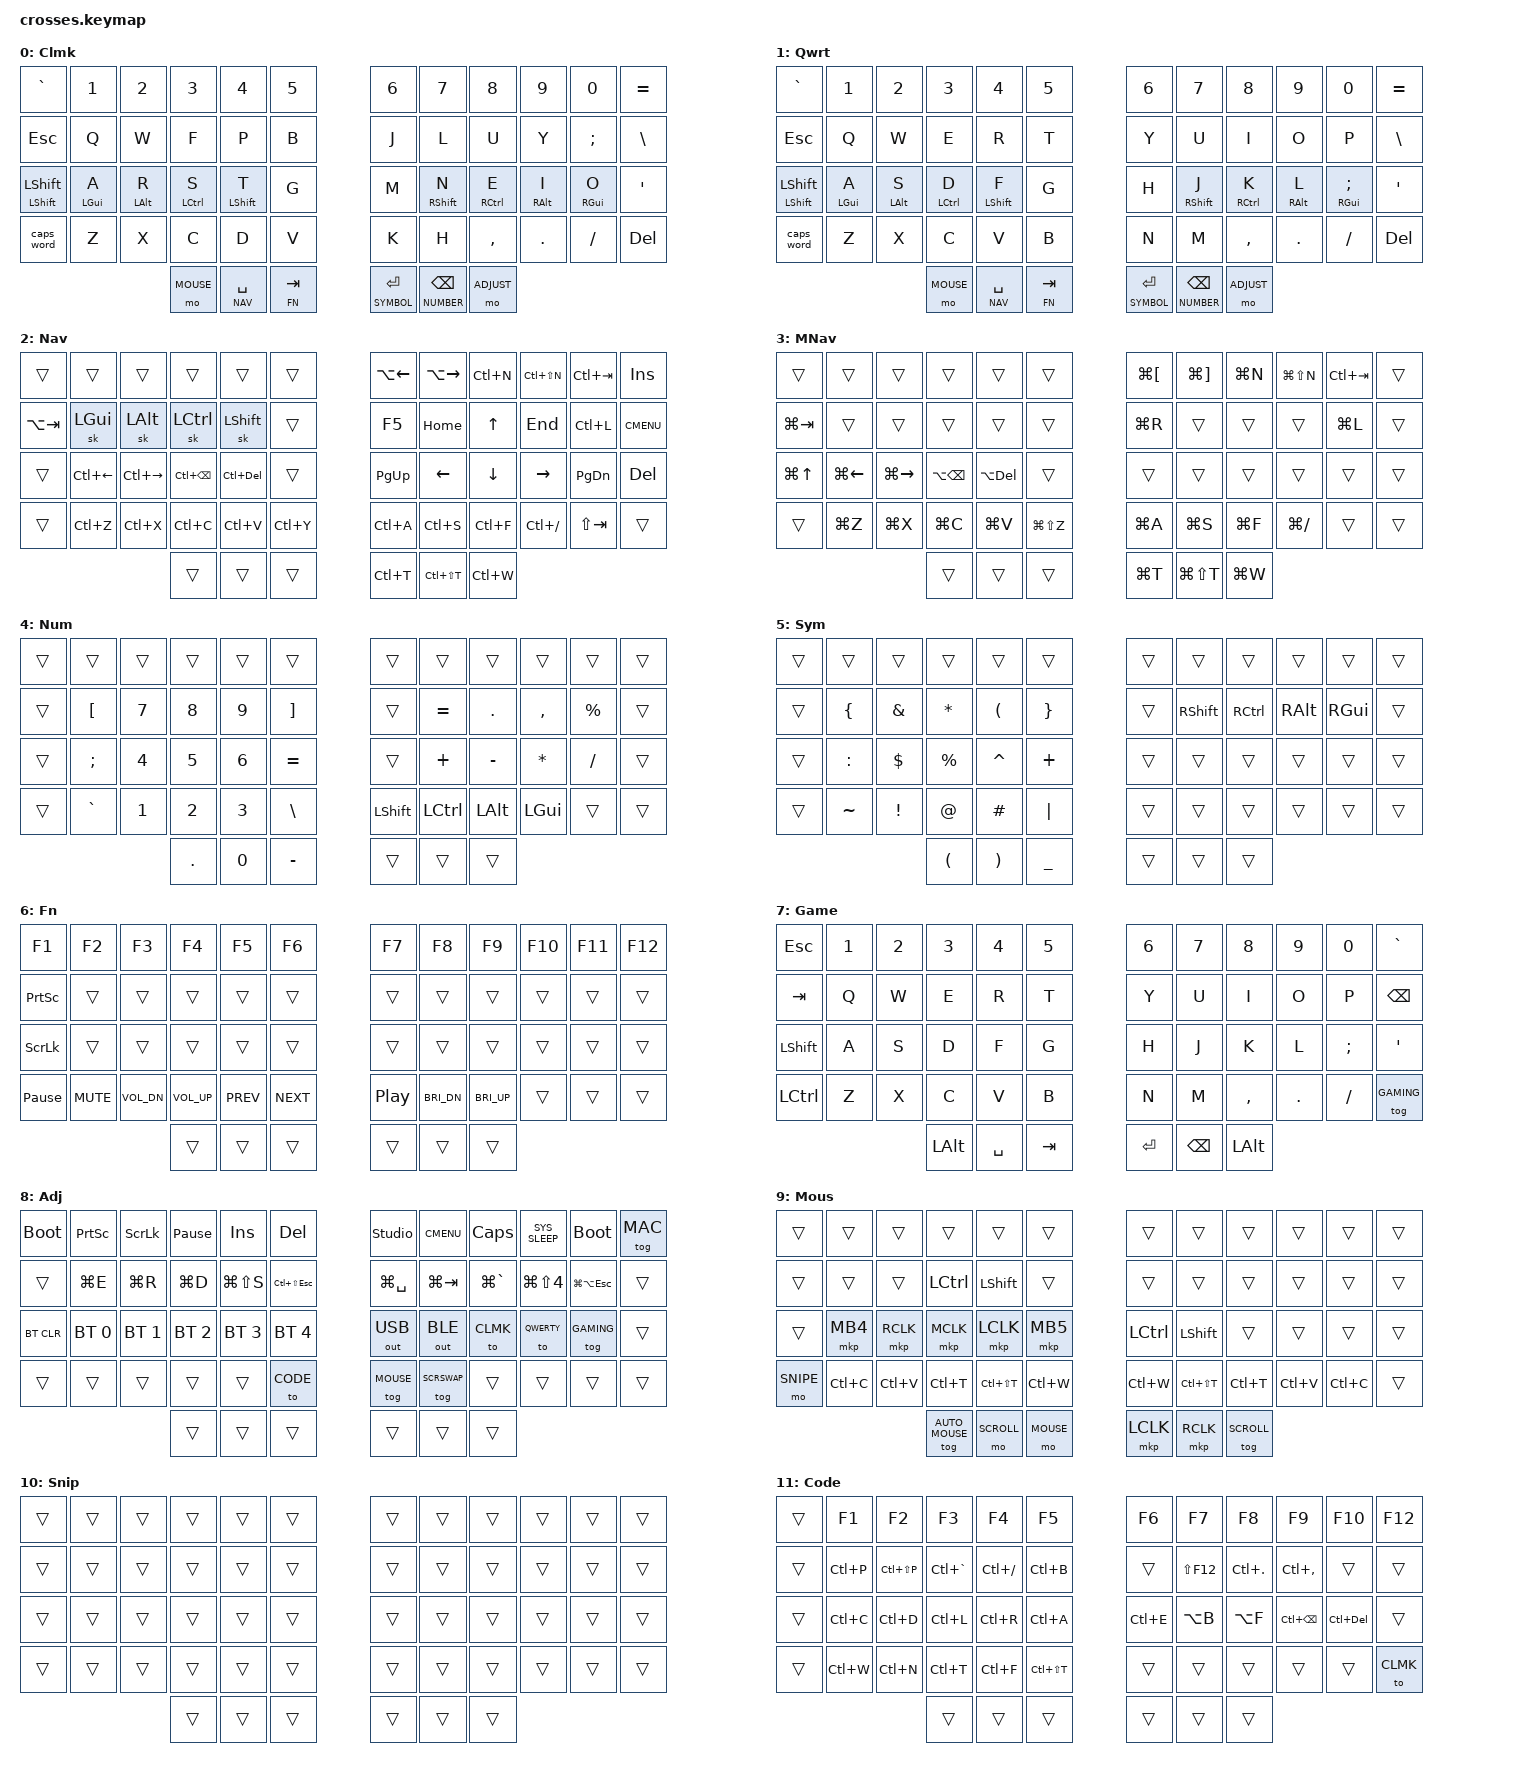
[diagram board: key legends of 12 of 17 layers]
#include <behaviors.dtsi>
#include <dt-bindings/zmk/bt.h>
#include <dt-bindings/zmk/keys.h>
#include <dt-bindings/zmk/outputs.h>
#include <dt-bindings/zmk/pointing.h>

#define CLMK     0
#define QWERTY   1
#define NAV      2
#define MAC_NAV  3
#define NUMBER   4
#define SYMBOL   5
#define FN       6
#define GAMING   7
#define ADJUST   8
#define MOUSE    9
#define SNIPE    10
#define CODE     11
#define MAC      12
#define SCRSWAP    13
#define SCROLL     14
#define AUTO_MOUSE 15
#define MAC_MOUSE  16

#define ___ &trans
#define XXX &none

&caps_word {
    continue-list = <MINUS UNDERSCORE BACKSPACE DELETE N0 N1 N2 N3 N4 N5 N6 N7 N8 N9>;
};

&lt {
    flavor = "balanced";
    tapping-term-ms = <200>;
    // Tap, then re-press within 200ms: the second press is treated as a tap
    // even when held. Lets you hold the BSPC/SPACE thumb to repeat after a
    // first tap, instead of triggering the layer.
    quick-tap-ms = <200>;
};

&mt {
    flavor = "tap-preferred";
    tapping-term-ms = <220>;
    quick-tap-ms = <175>;
};

&sk {
    release-after-ms = <900>;
    quick-release;
};

/ {
    behaviors {
        hml: homerow_mod_left {
            compatible = "zmk,behavior-hold-tap";
            #binding-cells = <2>;
            flavor = "balanced";
            tapping-term-ms = <220>;
            quick-tap-ms = <175>;
            require-prior-idle-ms = <150>;
            hold-trigger-on-release;
            bindings = <&kp>, <&kp>;
            hold-trigger-key-positions = <6 7 8 9 10 11 18 19 20 21 22 23 30 31 32 33 34 35 42 43 44 45 46 47 51 52 53>;
        };

        hmr: homerow_mod_right {
            compatible = "zmk,behavior-hold-tap";
            #binding-cells = <2>;
            flavor = "balanced";
            tapping-term-ms = <220>;
            quick-tap-ms = <175>;
            require-prior-idle-ms = <150>;
            hold-trigger-on-release;
            bindings = <&kp>, <&kp>;
            hold-trigger-key-positions = <0 1 2 3 4 5 12 13 14 15 16 17 24 25 26 27 28 29 36 37 38 39 40 41 48 49 50>;
        };

        magic_shift: magic_shift {
            compatible = "zmk,behavior-hold-tap";
            #binding-cells = <2>;
            flavor = "balanced";
            tapping-term-ms = <200>;
            quick-tap-ms = <175>;
            bindings = <&kp>, <&sk>;
        };
    };

    macros {
        // Modifier-held mouse clicks for the Mouse layer. The macro presses
        // the modifier, taps left click, releases the modifier so OS sees a
        // proper Ctrl-click / Shift-click / Cmd-click event.
        ctrl_click: ctrl_click {
            compatible = "zmk,behavior-macro";
            #binding-cells = <0>;
            bindings
                = <&macro_press &kp LCTRL>
                , <&macro_tap &mkp LCLK>
                , <&macro_release &kp LCTRL>
                ;
        };
        shift_click: shift_click {
            compatible = "zmk,behavior-macro";
            #binding-cells = <0>;
            bindings
                = <&macro_press &kp LSHFT>
                , <&macro_tap &mkp LCLK>
                , <&macro_release &kp LSHFT>
                ;
        };
        cmd_click: cmd_click {
            compatible = "zmk,behavior-macro";
            #binding-cells = <0>;
            bindings
                = <&macro_press &kp LGUI>
                , <&macro_tap &mkp LCLK>
                , <&macro_release &kp LGUI>
                ;
        };
    };

    conditional_layers {
        compatible = "zmk,conditional-layers";
        // While MAC mode is toggled on, holding NAV brings up the Mac-flavored
        // overlay that swaps Ctrl-prefixed clipboard/word ops to Cmd/Opt.
        mac_nav_overlay {
            if-layers = <NAV MAC>;
            then-layer = <MAC_NAV>;
        };
        // While MAC mode is toggled, the Mouse layer's modifier-click macros
        // swap to use Cmd instead of Ctrl.
        mac_mouse_overlay {
            if-layers = <MOUSE MAC>;
            then-layer = <MAC_MOUSE>;
        };
        mac_auto_mouse_overlay {
            if-layers = <AUTO_MOUSE MAC>;
            then-layer = <MAC_MOUSE>;
        };
    };

    combos {
        compatible = "zmk,combos";
        // urob-style: short timeout (~30ms) + require-prior-idle (150ms) so
        // the combo only fires when you've been idle for a moment, not in
        // the middle of a fast roll. Layer-restricted to base alphas.

        // MAC toggle: Z + / (bottom-row diagonal corners). Deliberate.
        combo_mac_toggle {
            timeout-ms = <50>;
            require-prior-idle-ms = <150>;
            key-positions = <37 46>;
            bindings = <&tog MAC>;
            layers = <CLMK QWERTY>;
        };
        // Parens on the right home row: N+E and E+I. Fires Ctrl/Cmd-correct
        // characters via &kp LPAR/RPAR (these are scancodes, not modifier
        // shortcuts, so they work the same on Win and Mac).
        combo_lpar {
            timeout-ms = <30>;
            require-prior-idle-ms = <150>;
            key-positions = <31 32>;
            bindings = <&kp LPAR>;
            layers = <CLMK QWERTY>;
        };
        combo_rpar {
            timeout-ms = <30>;
            require-prior-idle-ms = <150>;
            key-positions = <32 33>;
            bindings = <&kp RPAR>;
            layers = <CLMK QWERTY>;
        };
        // Cut/Copy/Paste on the left bottom row, urob-style. These fire
        // Ctrl-prefixed shortcuts; use Mouse/MacMouse for OS-aware commands.
        combo_copy {
            timeout-ms = <30>;
            require-prior-idle-ms = <150>;
            key-positions = <38 39>;
            bindings = <&kp LC(C)>;
            layers = <CLMK QWERTY>;
        };
        combo_paste {
            timeout-ms = <30>;
            require-prior-idle-ms = <150>;
            key-positions = <39 40>;
            bindings = <&kp LC(V)>;
            layers = <CLMK QWERTY>;
        };
        combo_cut {
            timeout-ms = <30>;
            require-prior-idle-ms = <150>;
            key-positions = <38 40>;
            bindings = <&kp LC(X)>;
            layers = <CLMK QWERTY>;
        };
        combo_square_left {
            timeout-ms = <30>;
            require-prior-idle-ms = <150>;
            key-positions = <43 44>;
            bindings = <&kp LBKT>;
            layers = <CLMK QWERTY>;
        };
        combo_square_right {
            timeout-ms = <30>;
            require-prior-idle-ms = <150>;
            key-positions = <44 45>;
            bindings = <&kp RBKT>;
            layers = <CLMK QWERTY>;
        };
        combo_gaming_toggle {
            timeout-ms = <50>;
            require-prior-idle-ms = <150>;
            key-positions = <38 45>;
            bindings = <&tog GAMING>;
            layers = <CLMK QWERTY>;
        };
    };

    chosen { zmk,physical-layout = &gggw_crosses_54_layout; };

    keymap {
        compatible = "zmk,keymap";

        clmk_layer {
            display-name = "Clmk";
            bindings = <
                &kp GRAVE      &kp N1        &kp N2        &kp N3        &kp N4          &kp N5        &kp N6       &kp N7          &kp N8        &kp N9       &kp N0         &kp EQUAL
                &kp ESC        &kp Q         &kp W         &kp F         &kp P           &kp B         &kp J        &kp L           &kp U         &kp Y        &kp SEMI       &kp BSLH
                &magic_shift LSHFT LSHFT &hml LGUI A &hml LALT R &hml LCTRL S &hml LSHFT T &kp G        &kp M        &hmr RSHFT N    &hmr RCTRL E  &hmr RALT I  &hmr RGUI O    &kp SQT
                &caps_word     &kp Z         &kp X         &kp C         &kp D           &kp V         &kp K        &kp H           &kp COMMA     &kp DOT      &kp FSLH       &kp DEL
                                                            &mo MOUSE                   &lt NAV SPACE &lt FN TAB   &lt SYMBOL RET  &lt NUMBER BSPC &mo ADJUST
            >;
        };

        qwerty_layer {
            display-name = "Qwrt";
            bindings = <
                &kp GRAVE      &kp N1        &kp N2        &kp N3        &kp N4          &kp N5        &kp N6       &kp N7          &kp N8        &kp N9       &kp N0         &kp EQUAL
                &kp ESC        &kp Q         &kp W         &kp E         &kp R           &kp T         &kp Y        &kp U           &kp I         &kp O        &kp P          &kp BSLH
                &magic_shift LSHFT LSHFT &hml LGUI A &hml LALT S &hml LCTRL D &hml LSHFT F &kp G        &kp H        &hmr RSHFT J    &hmr RCTRL K  &hmr RALT L  &hmr RGUI SEMI &kp SQT
                &caps_word     &kp Z         &kp X         &kp C         &kp V           &kp B         &kp N        &kp M           &kp COMMA     &kp DOT      &kp FSLH       &kp DEL
                                                            &mo MOUSE                   &lt NAV SPACE &lt FN TAB   &lt SYMBOL RET  &lt NUMBER BSPC &mo ADJUST
            >;
        };

        nav_layer {
            display-name = "Nav";
            // Row 1 left = clipboard ops with explicit Ctrl modifiers (the
            // K_UNDO/K_CUT system keycodes are inert on Win and Mac).
            // Arrows on row 3 (home row) so they sit under your right hand.
            // Row 2 right is the wider nav cluster (Home/PgDn/PgUp/End).
            bindings = <
                ___            ___           ___           ___           ___             ___           &kp LA(LEFT) &kp LA(RIGHT)   &kp LC(N)     &kp LC(LS(N)) &kp LC(TAB)   &kp INS
                &kp LA(TAB)    &sk LGUI      &sk LALT      &sk LCTRL     &sk LSHFT       ___           &kp F5       &kp HOME        &kp UP        &kp END      &kp LC(L)      &kp K_CMENU
                ___            &kp LC(LEFT)  &kp LC(RIGHT) &kp LC(BSPC)  &kp LC(DEL)     ___           &kp PG_UP    &kp LEFT        &kp DOWN      &kp RIGHT    &kp PG_DN      &kp DEL
                ___            &kp LC(Z)     &kp LC(X)     &kp LC(C)     &kp LC(V)       &kp LC(Y)     &kp LC(A)    &kp LC(S)       &kp LC(F)     &kp LC(FSLH) &kp LS(TAB)    ___
                                                            ___                       ___           ___          &kp LC(T)       &kp LC(LS(T)) &kp LC(W)
            >;
        };

        mac_nav_layer {
            display-name = "MNav";
            // Conditional overlay; only fires when MAC + NAV are both active.
            // Overrides only the keys whose modifier differs on macOS.
            // Cmd+Shift+Z is Mac redo. Word motion uses Opt instead of Ctrl.
            bindings = <
                ___            ___           ___           ___           ___             ___           &kp LG(LBKT) &kp LG(RBKT)    &kp LG(N)     &kp LG(LS(N)) &kp LC(TAB)   ___
                &kp LG(TAB)    ___           ___           ___           ___             ___           &kp LG(R)    ___             ___           ___          &kp LG(L)      ___
                &kp LG(UP)     &kp LG(LEFT)  &kp LG(RIGHT) &kp LA(BSPC)  &kp LA(DEL)     ___           ___          ___             ___           ___          ___            ___
                ___            &kp LG(Z)     &kp LG(X)     &kp LG(C)     &kp LG(V)       &kp LG(LS(Z)) &kp LG(A)    &kp LG(S)       &kp LG(F)     &kp LG(FSLH) ___            ___
                                                            ___                       ___           ___          &kp LG(T)       &kp LG(LS(T)) &kp LG(W)
            >;
        };

        number_layer {
            display-name = "Num";
            bindings = <
                ___            ___           ___           ___           ___             ___           ___          ___            ___          ___         ___            ___
                ___            &kp LBKT      &kp N7        &kp N8        &kp N9          &kp RBKT      ___          &kp EQUAL      &kp DOT      &kp COMMA   &kp PRCNT      ___
                ___            &kp SEMI      &kp N4        &kp N5        &kp N6          &kp EQUAL     ___          &kp PLUS       &kp MINUS    &kp ASTRK   &kp FSLH       ___
                ___            &kp GRAVE     &kp N1        &kp N2        &kp N3          &kp BSLH      &kp LSHFT    &kp LCTRL      &kp LALT     &kp LGUI    ___            ___
                                                            &kp DOT                   &kp N0        &kp MINUS    ___             ___           ___
            >;
        };

        symbol_layer {
            display-name = "Sym";
            bindings = <
                ___            ___           ___           ___           ___             ___           ___          ___            ___          ___         ___            ___
                ___            &kp LBRC      &kp AMPS      &kp ASTRK     &kp LPAR        &kp RBRC      ___          &kp RSHFT      &kp RCTRL    &kp RALT    &kp RGUI       ___
                ___            &kp COLON     &kp DLLR      &kp PRCNT     &kp CARET       &kp PLUS      ___          ___            ___          ___         ___            ___
                ___            &kp TILDE     &kp EXCL      &kp AT        &kp HASH        &kp PIPE      ___          ___            ___          ___         ___            ___
                                                            &kp LPAR                  &kp RPAR      &kp UNDER    ___             ___           ___
            >;
        };

        fn_layer {
            display-name = "Fn";
            // Cleaned out: just F-keys, system, and media. IDE and terminal
            // shortcuts moved to the Code layer.
            bindings = <
                &kp F1         &kp F2        &kp F3        &kp F4        &kp F5          &kp F6        &kp F7       &kp F8         &kp F9       &kp F10     &kp F11        &kp F12
                &kp PSCRN      ___           ___           ___           ___             ___           ___          ___            ___          ___         ___            ___
                &kp SLCK       ___           ___           ___           ___             ___           ___          ___            ___          ___         ___            ___
                &kp PAUSE_BREAK &kp C_MUTE   &kp C_VOL_DN  &kp C_VOL_UP  &kp C_PREV      &kp C_NEXT    &kp C_PLAY_PAUSE &kp C_BRI_DN &kp C_BRI_UP ___        ___            ___
                                                            ___                       ___           ___          ___             ___           ___
            >;
        };

        gaming_layer {
            display-name = "Game";
            bindings = <
                &kp ESC        &kp N1        &kp N2        &kp N3        &kp N4          &kp N5        &kp N6       &kp N7         &kp N8       &kp N9      &kp N0         &kp GRAVE
                &kp TAB        &kp Q         &kp W         &kp E         &kp R           &kp T         &kp Y        &kp U          &kp I        &kp O       &kp P          &kp BSPC
                &kp LSHFT      &kp A         &kp S         &kp D         &kp F           &kp G         &kp H        &kp J          &kp K        &kp L       &kp SEMI       &kp SQT
                &kp LCTRL      &kp Z         &kp X         &kp C         &kp V           &kp B         &kp N        &kp M          &kp COMMA    &kp DOT     &kp FSLH       &tog GAMING
                                                            &kp LALT                 &kp SPACE     &kp TAB      &kp RET        &kp BSPC      &kp LALT
            >;
        };

        adjust_layer {
            display-name = "Adj";
            // Reached by chording NAV (left thumb) + SYMBOL (right thumb).
            // Row 2 OS shortcuts are Windows-flavored; swap MAC on (row 1
            // col 11) for the Mac overlay (currently only adjusts Nav).
            bindings = <
                &bootloader    &kp PSCRN     &kp SLCK      &kp PAUSE_BREAK &kp INS       &kp DEL       &studio_unlock &kp K_CMENU   &kp CAPSLOCK &kp SYS_SLEEP &bootloader   &tog MAC
                ___            &kp LG(E)     &kp LG(R)     &kp LG(D)       &kp LG(LS(S)) &kp LC(LS(ESC)) &kp LG(SPACE) &kp LG(TAB)   &kp LG(GRAVE) &kp LG(LS(N4)) &kp LG(LA(ESC)) ___
                &bt BT_CLR     &bt BT_SEL 0  &bt BT_SEL 1  &bt BT_SEL 2    &bt BT_SEL 3  &bt BT_SEL 4  &out OUT_USB  &out OUT_BLE  &to CLMK      &to QWERTY    &tog GAMING   ___
                ___            ___           ___           ___             ___           &to CODE      &tog MOUSE    &tog SCRSWAP  ___           ___          ___           ___
                                                            ___                       ___           ___          ___             ___           ___
            >;
        };

        mouse_layer {
            display-name = "Mous";
            // Held momentarily via &mo MOUSE on the left outer thumb, or
            // toggled from Adjust. Click cluster on the left half.
            // Ctrl/Shift are available above MCLK/LCLK and on the left edge
            // of the right click row for one-handed modified clicks.
            // Hold &mo SNIPE (left bottom) for precision. Bottom row has
            // mirrored browser/edit shortcuts; hold &mo SCROLL (left middle
            // thumb) to turn the central ball into a scroll wheel.
            bindings = <
                ___            ___           ___           ___           ___            ___           ___          ___            ___          ___         ___            ___
                ___            ___           ___           &kp LCTRL     &kp LSHFT      ___           ___          ___            ___          ___         ___            ___
                ___            &mkp MB4      &mkp RCLK     &mkp MCLK     &mkp LCLK      &mkp MB5      &kp LCTRL    &kp LSHFT      ___          ___         ___            ___
                &mo SNIPE      &kp LC(C)     &kp LC(V)     &kp LC(T)     &kp LC(LS(T))  &kp LC(W)     &kp LC(W)    &kp LC(LS(T))  &kp LC(T)    &kp LC(V)   &kp LC(C)     ___
                                                            &tog AUTO_MOUSE           &mo SCROLL    &mo MOUSE    &mkp LCLK       &mkp RCLK     &tog SCROLL
            >;
        };

        snipe_layer {
            display-name = "Snip";
            // Activates the snipe override in the right overlay, halving the
            // central trackball to 200 cpi. Clicks fall through.
            bindings = <
                ___            ___           ___           ___           ___            ___           ___          ___            ___          ___         ___            ___
                ___            ___           ___           ___           ___            ___           ___          ___            ___          ___         ___            ___
                ___            ___           ___           ___           ___            ___           ___          ___            ___          ___         ___            ___
                ___            ___           ___           ___           ___            ___           ___          ___            ___          ___         ___            ___
                                                            ___                       ___           ___          ___             ___           ___
            >;
        };

        code_layer {
            display-name = "Code";
            // Reached via &to CODE on the Adjust layer. Right outer thumb
            // exits back to Clmk. IDE shortcuts on row 2; terminal shortcuts
            // on row 3.
            bindings = <
                ___            &kp F1        &kp F2        &kp F3        &kp F4          &kp F5        &kp F6       &kp F7         &kp F8       &kp F9      &kp F10        &kp F12
                ___            &kp LC(P)     &kp LC(LS(P)) &kp LC(GRAVE) &kp LC(FSLH)    &kp LC(B)     ___          &kp LS(F12)    &kp LC(DOT)  &kp LC(COMMA) ___          ___
                ___            &kp LC(C)     &kp LC(D)     &kp LC(L)     &kp LC(R)       &kp LC(A)     &kp LC(E)    &kp LA(B)      &kp LA(F)    &kp LC(BSPC) &kp LC(DEL)   ___
                ___            &kp LC(W)     &kp LC(N)     &kp LC(T)     &kp LC(F)       &kp LC(LS(T)) ___          ___            ___          ___          ___           &to CLMK
                                                            ___                       ___           ___          ___             ___           ___
            >;
        };

        mac_layer {
            display-name = "Mac";
            // Toggle flag layer. Mostly transparent; presence triggers the
            // MAC_NAV conditional overlay. Add per-position Mac overrides
            // here later if needed (Adjust OS shortcuts, etc.).
            bindings = <
                ___            ___           ___           ___           ___            ___           ___          ___            ___          ___         ___            ___
                ___            ___           ___           ___           ___            ___           ___          ___            ___          ___         ___            ___
                ___            ___           ___           ___           ___            ___           ___          ___            ___          ___         ___            ___
                ___            ___           ___           ___           ___            ___           ___          ___            ___          ___         ___            ___
                                                            ___                       ___           ___          ___             ___           ___
            >;
        };

        scrswap_layer {
            display-name = "Swap";
            // Toggle flag layer. Activates the scroll_swap_override on the
            // central listener and the pointer_swap_override on the peripheral
            // listener: right ball scrolls, left ball points.
            bindings = <
                ___            ___           ___           ___           ___            ___           ___          ___            ___          ___         ___            ___
                ___            ___           ___           ___           ___            ___           ___          ___            ___          ___         ___            ___
                ___            ___           ___           ___           ___            ___           ___          ___            ___          ___         ___            ___
                ___            ___           ___           ___           ___            ___           ___          ___            ___          ___         ___            ___
                                                            ___                       ___           ___          ___             ___           ___
            >;
        };

        scroll_layer {
            display-name = "Scrl";
            // Held flag layer triggered by &mo SCROLL on the Mouse layer.
            // Activates the momentary_scroll_override so the central ball
            // scrolls while the key is held. The right thumb toggles this
            // flag off even if the Mouse layer is no longer active.
            bindings = <
                ___            ___           ___           ___           ___            ___           ___          ___            ___          ___         ___            ___
                ___            ___           ___           ___           ___            ___           ___          ___            ___          ___         ___            ___
                ___            ___           ___           ___           ___            ___           ___          ___            ___          ___         ___            ___
                ___            ___           ___           ___           ___            ___           ___          ___            ___          ___         ___            ___
                                                            ___                       ___           ___          ___             ___           &tog SCROLL
            >;
        };

        auto_mouse_layer {
            display-name = "Auto";
            // Trackball-triggered temporary mouse layer. Kept separate from
            // MOUSE so the temp-layer timeout cannot deactivate a held
            // &mo MOUSE key.
            bindings = <
                ___            ___           ___           ___           ___            ___           ___          ___            ___          ___         ___            ___
                ___            ___           ___           &kp LCTRL     &kp LSHFT      ___           ___          ___            ___          ___         ___            ___
                ___            &mkp MB4      &mkp RCLK     &mkp MCLK     &mkp LCLK      &mkp MB5      &kp LCTRL    &kp LSHFT      ___          ___         ___            ___
                &mo SNIPE      &kp LC(C)     &kp LC(V)     &kp LC(T)     &kp LC(LS(T))  &kp LC(W)     &kp LC(W)    &kp LC(LS(T))  &kp LC(T)    &kp LC(V)   &kp LC(C)     ___
                                                            ___                       &mo SCROLL    &mo MOUSE    &mkp LCLK       &mkp RCLK     &tog SCROLL
            >;
        };

        mac_mouse_layer {
            display-name = "MMou";
            // Conditional overlay (MOUSE + MAC). Replaces Ctrl browser/edit
            // shortcuts with Cmd versions on the mirrored bottom row.
            bindings = <
                ___            ___           ___           ___           ___            ___           ___          ___            ___          ___         ___            ___
                ___            ___           ___           ___           ___            ___           ___          ___            ___          ___         ___            ___
                ___            ___           ___           ___           ___            ___           ___          ___            ___          ___         ___            ___
                ___            &kp LG(C)     &kp LG(V)     &kp LG(T)     &kp LG(LS(T))  &kp LG(W)     &kp LG(W)    &kp LG(LS(T))  &kp LG(T)    &kp LG(V)   &kp LG(C)     ___
                                                            ___                       ___           ___          ___             ___           ___
            >;
        };
    };
};
